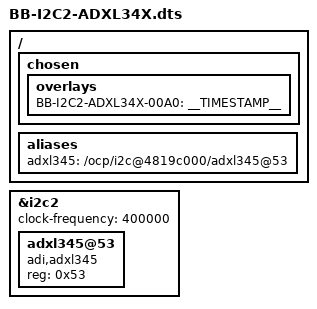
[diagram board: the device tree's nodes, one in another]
/*
 * Copyright (C) 2018 Seeed Studio
 * Peter Yang <turmary@126.com>
 *
 * MIT License
 *
 */
/dts-v1/;
/plugin/;

/ {
	/*
	 * Helper to show loaded overlays under: /proc/device-tree/chosen/overlays/
	 */
	fragment@0 {
		target-path="/";
		__overlay__ {
			chosen {
				overlays {
					BB-I2C2-ADXL34X-00A0 = __TIMESTAMP__;
				};
			};
		};
	};

	fragment@1 {
		target-path="/";
		__overlay__ {

			aliases {
				/* SLOT I2C1 */
				/*
				adxl345 = "/ocp/i2c@4802a000/adxl345@53";
				*/
				/* SLOT I2C2 */
				adxl345 = "/ocp/i2c@4819c000/adxl345@53";
			};
		};
	};

	fragment@2 {
		/* SLOT I2C1 */
		/*
		target = <&i2c1>;
		*/
		/* SLOT I2C2 */
		target = <&i2c2>;

		__overlay__ {
			status = "okay";

			clock-frequency = <400000>;

			#address-cells = <1>;
			#size-cells = <0>;

			adxl345@53 {
				compatible = "adi,adxl345";
				reg = <0x53>;
				status = "okay";
			};
		};
	};
};

